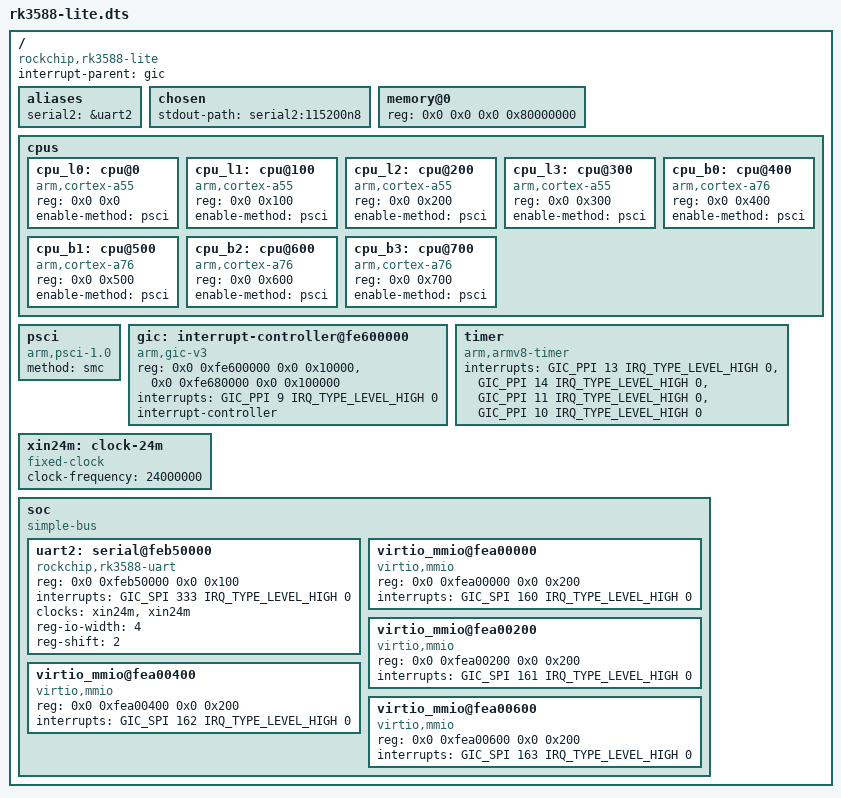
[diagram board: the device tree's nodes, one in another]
// SPDX-License-Identifier: (GPL-2.0+ OR MIT)
/*
 * rk3588-lite QEMU 机器的最小 DTS，只描述已建模设备，其余随机器模型按需迁入。
 * 异构拓扑照 rk3588-base.dtsi：A55@0x0-0x300，A76@0x400-0x700。
 * 与真板差异：uart 时钟 24MHz fixed-clock 替 CRU；无 ITS/dma/pinctrl；
 * virtio transports（0xfea00000+/SPI 160+）为 sim-only。
 * 真板控制台是 ttyFIQ0（FIQ 调试器，需 BL31）——sim 走普通 8250 路线。
 *
 * 编译（仓库根目录）：
 *   cpp -nostdinc -I third_party/src/rk3588-topeet/linux/include -undef \
 *       -x assembler-with-cpp boards/rk3588-topeet/sim/rk3588-lite.dts \
 *     | dtc -@ -I dts -O dtb -o boards/rk3588-topeet/sim/rk3588-lite.dtb -
 */

/dts-v1/;

#include <dt-bindings/interrupt-controller/arm-gic.h>
#include <dt-bindings/interrupt-controller/irq.h>

/ {
	compatible = "rockchip,rk3588-lite", "rockchip,rk3588";
	#address-cells = <2>;
	#size-cells = <2>;
	interrupt-parent = <&gic>;

	aliases {
		serial2 = &uart2;
	};

	chosen {
		stdout-path = "serial2:115200n8";
	};

	memory@0 {
		device_type = "memory";
		reg = <0x0 0x0 0x0 0x80000000>;	/* 2G @ 0，与机器模型一致 */
	};

	cpus {
		#address-cells = <2>;
		#size-cells = <0>;

		cpu_l0: cpu@0 { device_type = "cpu"; compatible = "arm,cortex-a55"; reg = <0x0 0x0>; enable-method = "psci"; };
		cpu_l1: cpu@100 { device_type = "cpu"; compatible = "arm,cortex-a55"; reg = <0x0 0x100>; enable-method = "psci"; };
		cpu_l2: cpu@200 { device_type = "cpu"; compatible = "arm,cortex-a55"; reg = <0x0 0x200>; enable-method = "psci"; };
		cpu_l3: cpu@300 { device_type = "cpu"; compatible = "arm,cortex-a55"; reg = <0x0 0x300>; enable-method = "psci"; };
		cpu_b0: cpu@400 { device_type = "cpu"; compatible = "arm,cortex-a76"; reg = <0x0 0x400>; enable-method = "psci"; };
		cpu_b1: cpu@500 { device_type = "cpu"; compatible = "arm,cortex-a76"; reg = <0x0 0x500>; enable-method = "psci"; };
		cpu_b2: cpu@600 { device_type = "cpu"; compatible = "arm,cortex-a76"; reg = <0x0 0x600>; enable-method = "psci"; };
		cpu_b3: cpu@700 { device_type = "cpu"; compatible = "arm,cortex-a76"; reg = <0x0 0x700>; enable-method = "psci"; };
	};

	psci {
		compatible = "arm,psci-1.0";
		method = "smc";
	};

	gic: interrupt-controller@fe600000 {
		compatible = "arm,gic-v3";
		reg = <0x0 0xfe600000 0x0 0x10000>,	/* GICD */
		      <0x0 0xfe680000 0x0 0x100000>;	/* GICR，8 核 */
		interrupts = <GIC_PPI 9 IRQ_TYPE_LEVEL_HIGH 0>;
		interrupt-controller;
		#interrupt-cells = <4>;
	};

	timer {
		compatible = "arm,armv8-timer";
		interrupts = <GIC_PPI 13 IRQ_TYPE_LEVEL_HIGH 0>,
			     <GIC_PPI 14 IRQ_TYPE_LEVEL_HIGH 0>,
			     <GIC_PPI 11 IRQ_TYPE_LEVEL_HIGH 0>,
			     <GIC_PPI 10 IRQ_TYPE_LEVEL_HIGH 0>;
	};

	xin24m: clock-24m {
		compatible = "fixed-clock";
		clock-frequency = <24000000>;
		#clock-cells = <0>;
	};

	soc {
		compatible = "simple-bus";
		#address-cells = <2>;
		#size-cells = <2>;
		ranges;

		uart2: serial@feb50000 {
			compatible = "rockchip,rk3588-uart", "snps,dw-apb-uart";
			reg = <0x0 0xfeb50000 0x0 0x100>;
			interrupts = <GIC_SPI 333 IRQ_TYPE_LEVEL_HIGH 0>;
			clocks = <&xin24m>, <&xin24m>;
			clock-names = "baudclk", "apb_pclk";
			reg-io-width = <4>;
			reg-shift = <2>;
			status = "okay";
		};

		/* QEMU sim-only transports（0xfea00000+ / SPI 160+），与机器模型一致 */
		virtio_mmio@fea00000 {
			compatible = "virtio,mmio";
			reg = <0x0 0xfea00000 0x0 0x200>;
			interrupts = <GIC_SPI 160 IRQ_TYPE_LEVEL_HIGH 0>;
		};
		virtio_mmio@fea00200 {
			compatible = "virtio,mmio";
			reg = <0x0 0xfea00200 0x0 0x200>;
			interrupts = <GIC_SPI 161 IRQ_TYPE_LEVEL_HIGH 0>;
		};
		virtio_mmio@fea00400 {
			compatible = "virtio,mmio";
			reg = <0x0 0xfea00400 0x0 0x200>;
			interrupts = <GIC_SPI 162 IRQ_TYPE_LEVEL_HIGH 0>;
		};
		virtio_mmio@fea00600 {
			compatible = "virtio,mmio";
			reg = <0x0 0xfea00600 0x0 0x200>;
			interrupts = <GIC_SPI 163 IRQ_TYPE_LEVEL_HIGH 0>;
		};
	};
};
